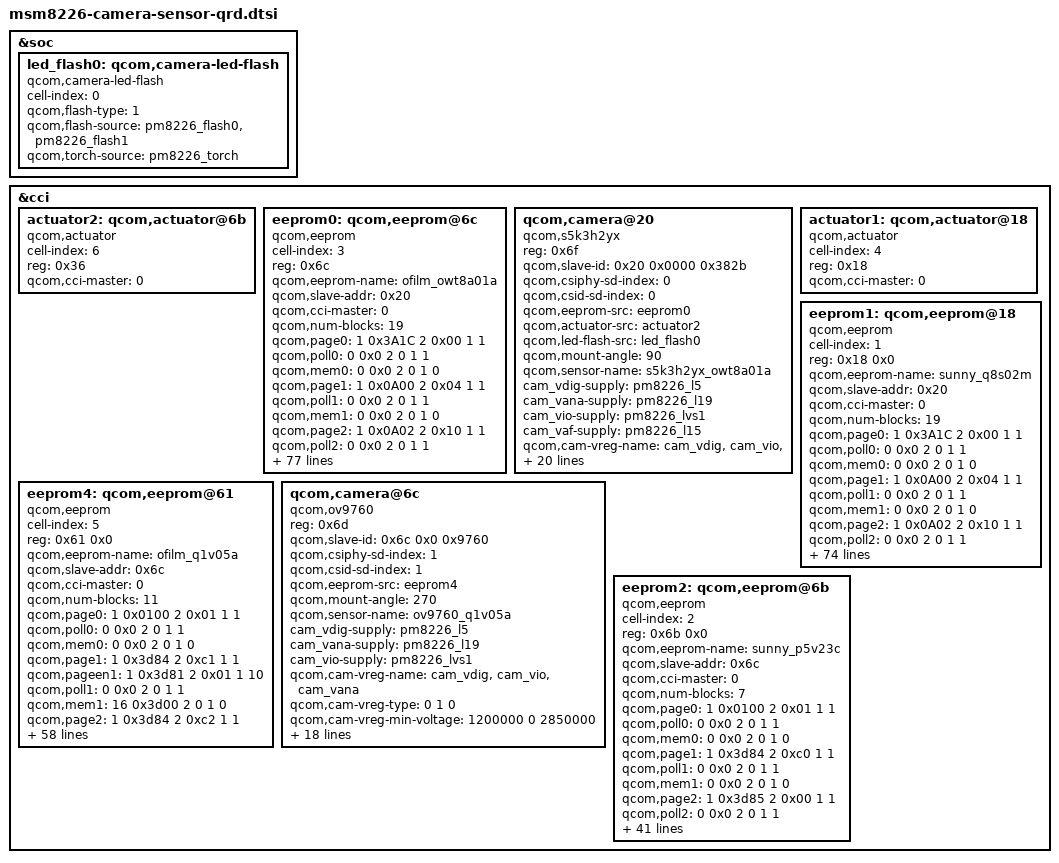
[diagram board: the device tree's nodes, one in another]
/*
 * Copyright (c) 2013, The Linux Foundation. All rights reserved.
 * Copyright (C) 2015 XiaoMi, Inc.
 *
 * This program is free software; you can redistribute it and/or modify
 * it under the terms of the GNU General Public License version 2 and
 * only version 2 as published by the Free Software Foundation.
 *
 * This program is distributed in the hope that it will be useful,
 * but WITHOUT ANY WARRANTY; without even the implied warranty of
 * MERCHANTABILITY or FITNESS FOR A PARTICULAR PURPOSE.  See the
 * GNU General Public License for more details.
 */

&soc {

	led_flash0: qcom,camera-led-flash {
		cell-index = <0>;
		compatible = "qcom,camera-led-flash";
		qcom,flash-type = <1>;
		qcom,flash-source = <&pm8226_flash0 &pm8226_flash1>;
		qcom,torch-source = <&pm8226_torch>;
	};
};

&cci {

	actuator2: qcom,actuator@6b {
		cell-index = <6>;
		reg = <0x36>;
		compatible = "qcom,actuator";
		qcom,cci-master = <0>;
	};

	eeprom0: qcom,eeprom@6c {
		cell-index = <3>;
		reg = <0x6c>;
		qcom,eeprom-name = "ofilm_owt8a01a";
		compatible = "qcom,eeprom";
		qcom,slave-addr = <0x20>;
		qcom,cci-master = <0>;

		qcom,num-blocks = <19>;

		qcom,page0 = <1 0x3A1C 2 0x00 1 1>;
		qcom,poll0 = <0 0x0 2 0 1 1>;
		qcom,mem0 = <0 0x0 2 0 1 0>;

		qcom,page1 = <1 0x0A00 2 0x04 1 1>;
		qcom,poll1 = <0 0x0 2 0 1 1>;
		qcom,mem1 = <0 0x0 2 0 1 0>;
		qcom,page2 = <1 0x0A02 2 0x10 1 1>;
		qcom,poll2 = <0 0x0 2 0 1 1>;
		qcom,mem2 = <0 0x0 2 0 1 0>;
		qcom,page3 = <1 0x0A00 2 0x01 1 20>;
		qcom,poll3 = <0 0x0 2 0 1 1>;
		qcom,mem3 = <8 0x0A04 2 0 1 1>;

		qcom,page4 = <1 0x0A00 2 0x04 1 1>;
		qcom,poll4 = <0 0x0 2 0 1 1>;
		qcom,mem4 = <0 0x0 2 0 1 0>;
		qcom,page5 = <1 0x0A02 2 0x11 1 1>;
		qcom,poll5 = <0 0x0 2 0 1 1>;
		qcom,mem5 = <0 0x00 2 0 1 0>;
		qcom,page6 = <1 0x0A00 2 0x01 1 20>;
		qcom,poll6 = <0 0x0 2 0 1 1>;
		qcom,mem6 = <8 0x0A04 2 0 1 1>;

		qcom,page7 = <1 0x0A00 2 0x04 1 1>;
		qcom,poll7 = <0 0x0 2 0 1 1>;
		qcom,mem7 = <0 0x0 2 0 1 0>;
		qcom,page8 = <1 0x0A02 2 0x12 1 10>;
		qcom,poll8 = <0 0x0 2 0 1 1>;
		qcom,mem8 = <0 0x0 2 0 1 0>;
		qcom,page9 = <1 0x0A00 2 0x01 1 20>;
		qcom,poll9 = <0 0x0 2 0 1 1>;
		qcom,mem9 = <8 0x0A04 2 0 1 1>;

		qcom,page10 = <1 0x0A00 2 0x04 1 1>;
		qcom,poll10 = <0 0x0 2 0 1 1>;
		qcom,mem10 = <0 0x0 2 0 1 0>;
		qcom,page11 = <1 0x0A02 2 0x09 1 10>;
		qcom,poll11 = <0 0x0 2 0 1 1>;
		qcom,mem11 = <0 0x0 2 0 1 0>;
		qcom,page12 = <1 0x0A00 2 0x01 1 20>;
		qcom,poll12 = <0 0x0 2 0 1 1>;
		qcom,mem12 = <3 0x0A04 2 0 1 1>;

		qcom,page13 = <1 0x0A00 2 0x04 1 1>;
		qcom,poll13 = <0 0x0 2 0 1 1>;
		qcom,mem13 = <0 0x0 2 0 1 0>;
		qcom,page14 = <1 0x0A00 2 0x00 1 1>;
		qcom,poll14 = <0 0x0 2 0 1 1>;
		qcom,mem14 = <0 0x0 2 0 1 0>;
		qcom,page15 = <1 0x0A04 2 0x08 1 1>;
		qcom,poll15 = <0 0x0 2 0 1 1>;
		qcom,mem15 = <0 0x0A04 2 0 1 0>;

		qcom,page16 = <1 0x0A04 2 0x03 1 1>;
		qcom,poll16 = <0 0x0 2 0 1 1>;
		qcom,mem16 = <9 0x0A04 2 0 1 1>;
		qcom,page17 = <1 0x0A04 2 0x03 1 1>;
		qcom,poll17 = <0 0x0 2 0 1 1>;
		qcom,mem17 = <9 0x0A04 2 0 1 1>;
		qcom,page18 = <1 0x0A04 2 0x03 1 1>;
		qcom,poll18 = <0 0x0 2 0 1 1>;
		qcom,mem18 = <0 0x0A04 2 0 1 1>;

		cam_vdig-supply = <&pm8226_l5>;
		cam_vana-supply = <&pm8226_l19>;
		cam_vio-supply = <&pm8226_lvs1>;
		qcom,cam-vreg-name = "cam_vdig","cam_vana", "cam_vio";
		qcom,cam-vreg-type = <0 1 2>;
		qcom,cam-vreg-min-voltage = <1200000 2850000 0>;
		qcom,cam-vreg-max-voltage = <1200000 2850000 0>;
		qcom,cam-vreg-op-mode = <200000 80000 0>;

		qcom,gpio-no-mux = <0>;
		gpios = <&msmgpio 26 0>,
				<&msmgpio 37 0>,
				<&msmgpio 36 0>;
		qcom,gpio-reset = <1>;
		qcom,gpio-standby = <2>;
		qcom,gpio-req-tbl-num = <0 1 2>;
		qcom,gpio-req-tbl-flags = <1 0 0>;
		qcom,gpio-req-tbl-label = "CAMIF_MCLK",
				"CAM_RESET1",
				"CAM_STANDBY";
		qcom,cam-power-seq-type = "sensor_vreg","sensor_vreg",
				"sensor_vreg", "sensor_clk",
				"sensor_gpio", "sensor_gpio",
				"sensor_gpio", "sensor_gpio";
		qcom,cam-power-seq-val = "cam_vdig","cam_vana",
				"cam_vio", "sensor_cam_mclk",
				"sensor_gpio_reset",
				"sensor_gpio_standby",
				"sensor_gpio_reset",
				"sensor_gpio_standby";
		qcom,cam-power-seq-cfg-val = <1 1 1 24000000 0 0 1 1>;
		qcom,cam-power-seq-delay = <1 1 1 20 10 10 10 10>;
	};

    qcom,camera@20 {
		compatible = "qcom,s5k3h2yx";
		reg = <0x6f>;
		qcom,slave-id = <0x20 0x0000 0x382b>;
		qcom,csiphy-sd-index = <0>;
		qcom,csid-sd-index = <0>;
		qcom,eeprom-src = <&eeprom0>;
		qcom,actuator-src = <&actuator2>;
		qcom,led-flash-src = <&led_flash0>;
		qcom,mount-angle = <90>;
		qcom,sensor-name = "s5k3h2yx_owt8a01a";
			cam_vdig-supply = <&pm8226_l5>;
			cam_vana-supply = <&pm8226_l19>;
			cam_vio-supply = <&pm8226_lvs1>;
			cam_vaf-supply = <&pm8226_l15>;
		qcom,cam-vreg-name = "cam_vdig", "cam_vio", "cam_vana",
			"cam_vaf";
		qcom,cam-vreg-type = <0 1 0 0>;
		qcom,cam-vreg-min-voltage = <1200000 0 2850000 2800000>;
		qcom,cam-vreg-max-voltage = <1200000 0 2850000 2800000>;
		qcom,cam-vreg-op-mode = <200000 0 80000 100000>;
		qcom,gpio-no-mux = <0>;
		gpios = <&msmgpio 26 0>,
				<&msmgpio 37 0>,
				<&msmgpio 36 0>;
		qcom,gpio-reset = <1>;
		qcom,gpio-standby = <2>;
		qcom,gpio-req-tbl-num = <0 1 2>;
		qcom,gpio-req-tbl-flags = <1 0 0>;
		qcom,gpio-req-tbl-label = "CAMIF_MCLK",
			"CAM_RESET1",
			"CAM_STANDBY";
		qcom,csi-lane-assign = <0x4320>;
		qcom,csi-lane-mask = <0x07>;
		qcom,sensor-position = <0>;
		qcom,sensor-mode = <1>;
		qcom,cci-master = <0>;
	};

	actuator1: qcom,actuator@18 {
		cell-index = <4>;
		reg = <0x18>;
		compatible = "qcom,actuator";
		qcom,cci-master = <0>;
	};

	eeprom1: qcom,eeprom@18 {
		cell-index = <1>;
		reg = <0x18 0x0>;
		qcom,eeprom-name = "sunny_q8s02m";
		compatible = "qcom,eeprom";
		qcom,slave-addr = <0x20>;
		qcom,cci-master = <0>;
		qcom,num-blocks = <19>;

		qcom,page0 = <1 0x3A1C 2 0x00 1 1>;
		qcom,poll0 = <0 0x0 2 0 1 1>;
		qcom,mem0 = <0 0x0 2 0 1 0>;

		qcom,page1 = <1 0x0A00 2 0x04 1 1>;
		qcom,poll1 = <0 0x0 2 0 1 1>;
		qcom,mem1 = <0 0x0 2 0 1 0>;
		qcom,page2 = <1 0x0A02 2 0x10 1 1>;
		qcom,poll2 = <0 0x0 2 0 1 1>;
		qcom,mem2 = <0 0x0 2 0 1 0>;
		qcom,page3 = <1 0x0A00 2 0x01 1 20>;
		qcom,poll3 = <0 0x0 2 0 1 1>;
		qcom,mem3 = <8 0x0A04 2 0 1 1>;

		qcom,page4 = <1 0x0A00 2 0x04 1 1>;
		qcom,poll4 = <0 0x0 2 0 1 1>;
		qcom,mem4 = <0 0x0 2 0 1 0>;
		qcom,page5 = <1 0x0A02 2 0x11 1 1>;
		qcom,poll5 = <0 0x0 2 0 1 1>;
		qcom,mem5 = <0 0x00 2 0 1 0>;
		qcom,page6 = <1 0x0A00 2 0x01 1 20>;
		qcom,poll6 = <0 0x0 2 0 1 1>;
		qcom,mem6 = <8 0x0A04 2 0 1 1>;

		qcom,page7 = <1 0x0A00 2 0x04 1 1>;
		qcom,poll7 = <0 0x0 2 0 1 1>;
		qcom,mem7 = <0 0x0 2 0 1 0>;
		qcom,page8 = <1 0x0A02 2 0x12 1 10>;
		qcom,poll8 = <0 0x0 2 0 1 1>;
		qcom,mem8 = <0 0x0 2 0 1 0>;
		qcom,page9 = <1 0x0A00 2 0x01 1 20>;
		qcom,poll9 = <0 0x0 2 0 1 1>;
		qcom,mem9 = <8 0x0A04 2 0 1 1>;

		qcom,page10 = <1 0x0A00 2 0x04 1 1>;
		qcom,poll10 = <0 0x0 2 0 1 1>;
		qcom,mem10 = <0 0x0 2 0 1 0>;
		qcom,page11 = <1 0x0A02 2 0x09 1 10>;
		qcom,poll11 = <0 0x0 2 0 1 1>;
		qcom,mem11 = <0 0x0 2 0 1 0>;
		qcom,page12 = <1 0x0A00 2 0x01 1 20>;
		qcom,poll12 = <0 0x0 2 0 1 1>;
		qcom,mem12 = <3 0x0A04 2 0 1 1>;

		qcom,page13 = <1 0x0A00 2 0x04 1 1>;
		qcom,poll13 = <0 0x0 2 0 1 1>;
		qcom,mem13 = <0 0x0 2 0 1 0>;
		qcom,page14 = <1 0x0A00 2 0x00 1 1>;
		qcom,poll14 = <0 0x0 2 0 1 1>;
		qcom,mem14 = <0 0x0 2 0 1 0>;
		qcom,page15 = <1 0x0A04 2 0x08 1 1>;
		qcom,poll15 = <0 0x0 2 0 1 1>;
		qcom,mem15 = <0 0x0A04 2 0 1 0>;

		qcom,page16 = <1 0x0A04 2 0x03 1 1>;
		qcom,poll16 = <0 0x0 2 0 1 1>;
		qcom,mem16 = <9 0x0A04 2 0 1 1>;
		qcom,page17 = <1 0x0A04 2 0x03 1 1>;
		qcom,poll17 = <0 0x0 2 0 1 1>;
		qcom,mem17 = <9 0x0A04 2 0 1 1>;
		qcom,page18 = <1 0x0A04 2 0x03 1 1>;
		qcom,poll18 = <0 0x0 2 0 1 1>;
		qcom,mem18 = <0 0x0A04 2 0 1 1>;

		cam_vdig-supply = <&pm8226_l5>;
		cam_vana-supply = <&pm8226_l19>;
		cam_vio-supply = <&pm8226_lvs1>;
		qcom,cam-vreg-name = "cam_vdig","cam_vana", "cam_vio";
		qcom,cam-vreg-type = <0 1 2>;
		qcom,cam-vreg-min-voltage = <1200000 2850000 0>;
		qcom,cam-vreg-max-voltage = <1200000 2850000 0>;
		qcom,cam-vreg-op-mode = <200000 80000 0>;
		qcom,gpio-no-mux = <0>;
		gpios = <&msmgpio 26 0>,
		        <&msmgpio 37 0>,
		        <&msmgpio 36 0>;
		qcom,gpio-reset = <1>;
		qcom,gpio-standby = <2>;
		qcom,gpio-req-tbl-num = <0 1 2>;
		qcom,gpio-req-tbl-flags = <1 0 0>;
		qcom,gpio-req-tbl-label = "CAMIF_MCLK",
		        "CAM_RESET1",
		        "CAM_STANDBY";
		qcom,cam-power-seq-type = "sensor_vreg","sensor_vreg",
		        "sensor_vreg", "sensor_clk",
		        "sensor_gpio", "sensor_gpio";
		qcom,cam-power-seq-val = "cam_vdig","cam_vana",
		        "cam_vio", "sensor_cam_mclk",
		        "sensor_gpio_reset",
		        "sensor_gpio_standby";
		qcom,cam-power-seq-cfg-val = <1 1 1 24000000 1 1>;
		qcom,cam-power-seq-delay = <1 1 1 5 5 10>;
	};

    eeprom4: qcom,eeprom@61{
		cell-index = <5>;
		reg = <0x61 0x0>;
		qcom,eeprom-name = "ofilm_q1v05a";
		compatible = "qcom,eeprom";
		qcom,slave-addr = <0x6c>;
		qcom,cci-master = <0>;
		qcom,num-blocks = <11>;

		qcom,page0 = <1 0x0100 2 0x01 1 1>;
		qcom,poll0 = <0 0x0 2 0 1 1>;
		qcom,mem0 = <0 0x0 2 0 1 0>;
		qcom,page1 = <1 0x3d84 2 0xc1 1 1>;
		qcom,pageen1 = <1 0x3d81 2 0x01 1 10>;
		qcom,poll1 = <0 0x0 2 0 1 1>;
		qcom,mem1 = <16 0x3d00 2 0 1 0>;
		qcom,page2 = <1 0x3d84 2 0xc2 1 1>;
		qcom,pageen2 = <1 0x3d81 2 0x01 1 10>;
		qcom,poll2 = <0 0x0 2 0 1 1>;
		qcom,mem2 = <16 0x3d00 2 0 1 0>;
		qcom,page3 = <1 0x3d84 2 0xc3 1 1>;
		qcom,pageen3 = <1 0x3d81 2 0x01 1 10>;
		qcom,poll3 = <0 0x0 2 0 1 1>;
		qcom,mem3 = <16 0x3d00 2 0 1 0>;
		qcom,page4 = <1 0x3d84 2 0xc4 1 1>;
		qcom,pageen4 = <1 0x3d81 2 0x01 1 10>;
		qcom,poll4 = <0 0x0 2 0 1 1>;
		qcom,mem4 = <16 0x3d00 2 0 1 0>;
		qcom,page5 = <1 0x3d84 2 0xc5 1 1>;
		qcom,pageen5 = <1 0x3d81 2 0x01 1 10>;
		qcom,poll5 = <0 0x0 2 0 1 1>;
		qcom,mem5 = <16 0x3d00 2 0 1 0>;
		qcom,page6 = <1 0x3d84 2 0xc6 1 1>;
		qcom,pageen6 = <1 0x3d81 2 0x01 1 10>;
		qcom,poll6 = <0 0x0 2 0 1 1>;
		qcom,mem6 = <16 0x3d00 2 0 1 0>;
		qcom,page7 = <1 0x3d84 2 0xc7 1 1>;
		qcom,pageen7 = <1 0x3d81 2 0x01 1 10>;
		qcom,poll7 = <0 0x0 2 0 1 1>;
		qcom,mem7 = <16 0x3d00 2 0 1 0>;
		qcom,page8 = <1 0x3d84 2 0xc8 1 1>;
		qcom,pageen8 = <1 0x3d81 2 0x01 1 10>;
		qcom,poll8 = <0 0x0 2 0 1 1>;
		qcom,mem8 = <16 0x3d00 2 0 1 0>;
		qcom,page9 = <1 0x3d84 2 0xc9 1 1>;
		qcom,pageen9 = <1 0x3d81 2 0x01 1 10>;
		qcom,poll9 = <0 0x0 2 0 1 1>;
		qcom,mem9 = <16 0x3d00 2 0 1 0>;
		qcom,page10 = <1 0x3d84 2 0xdf 1 1>;
		qcom,pageen10 = <1 0x3d81 2 0x01 1 10>;
		qcom,poll10 = <0 0x0 2 0 1 1>;
		qcom,mem10 = <16 0x3d00 2 0 1 0>;

		cam_vio-supply = <&pm8226_lvs1>;
		cam_vdig-supply = <&pm8226_l5>;
		qcom,cam-vreg-name = "cam_vdig", "cam_vio";
		qcom,cam-vreg-type = <0 1>;
		qcom,cam-vreg-min-voltage = <1200000 0>;
		qcom,cam-vreg-max-voltage = <1200000 0>;
		qcom,cam-vreg-op-mode = <200000 0>;
		qcom,gpio-no-mux = <0>;
		gpios = <&msmgpio 26 0>,
				<&msmgpio 28 0>,
				<&msmgpio 35 0>;
		qcom,gpio-reset = <1>;
		qcom,gpio-standby = <2>;
		qcom,gpio-req-tbl-num = <0 1 2>;
		qcom,gpio-req-tbl-flags = <1 0 0>;
		qcom,gpio-req-tbl-label = "CAMIF_MCLK",
			"CAM_RESET",
			"CAM_STANDBY";
		qcom,cam-power-seq-type = "sensor_vreg",
			"sensor_vreg","sensor_clk","sensor_gpio",
			"sensor_gpio";
		qcom,cam-power-seq-val = "cam_vdig","cam_vio",
			"sensor_cam_mclk","sensor_gpio_reset",
			"sensor_gpio_standby";
		qcom,cam-power-seq-cfg-val = <1 1 24000000 1 1>;
		qcom,cam-power-seq-delay = <1 1 10 10 10>;
	};

	qcom,camera@6c {
		compatible = "qcom,ov9760";
		reg = <0x6d>;
		qcom,slave-id = <0x6c 0x0 0x9760>;
		qcom,csiphy-sd-index = <1>;
		qcom,csid-sd-index = <1>;
		qcom,eeprom-src = <&eeprom4>;
		qcom,mount-angle = <270>;
		qcom,sensor-name = "ov9760_q1v05a";
		cam_vdig-supply = <&pm8226_l5>;
		cam_vana-supply = <&pm8226_l19>;
		cam_vio-supply = <&pm8226_lvs1>;
		qcom,cam-vreg-name = "cam_vdig", "cam_vio", "cam_vana";
		qcom,cam-vreg-type = <0 1 0>;
		qcom,cam-vreg-min-voltage = <1200000 0 2850000>;
		qcom,cam-vreg-max-voltage = <1200000 0 2850000>;
		qcom,cam-vreg-op-mode = <200000 0 80000>;
		qcom,gpio-no-mux = <0>;
		gpios = <&msmgpio 26 0>,
				<&msmgpio 28 0>,
				<&msmgpio 35 0>;
		qcom,gpio-reset = <1>;
		qcom,gpio-standby = <2>;
		qcom,gpio-req-tbl-num = <0 1 2>;
		qcom,gpio-req-tbl-flags = <1 0 0>;
		qcom,gpio-req-tbl-label = "CAMIF_MCLK",
				"CAM_RESET",
				"CAM_STANDBY";
		qcom,gpio-set-tbl-num = <1 1>;
		qcom,gpio-set-tbl-flags = <0 2>;
		qcom,gpio-set-tbl-delay = <1000 4000>;
		qcom,csi-lane-assign = <0x4320>;
		qcom,csi-lane-mask = <0x3>;
		qcom,sensor-position = <1>;
		qcom,sensor-mode = <1>;
		qcom,cci-master = <0>;
		status = "ok";
	};

	eeprom2: qcom,eeprom@6b{
		cell-index = <2>;
		reg = <0x6b 0x0>;
		qcom,eeprom-name = "sunny_p5v23c";
		compatible = "qcom,eeprom";
		qcom,slave-addr = <0x6c>;
		qcom,cci-master = <0>;
		qcom,num-blocks = <7>;

		qcom,page0 = <1 0x0100 2 0x01 1 1>;
		qcom,poll0 = <0 0x0 2 0 1 1>;
		qcom,mem0 = <0 0x0 2 0 1 0>;

		qcom,page1 = <1 0x3d84 2 0xc0 1 1>;
		qcom,poll1 = <0 0x0 2 0 1 1>;
		qcom,mem1 = <0 0x0 2 0 1 0>;
		qcom,page2 = <1 0x3d85 2 0x00 1 1>;
		qcom,poll2 = <0 0x0 2 0 1 1>;
		qcom,mem2 = <0 0x0 2 0 1 0>;
		qcom,page3 = <1 0x3d86 2 0x0f 1 1>;
		qcom,pageen3 = <1 0x3d81 2 0x01 1 10>;
		qcom,poll3 = <0 0x0 2 0 1 1>;
		qcom,mem3 = <16 0x3d00 2 0 1 0>;

		qcom,page4 = <1 0x3d84 2 0xc0 1 1>;
		qcom,poll4 = <0 0x0 2 0 1 1>;
		qcom,mem4 = <0 0x0 2 0 1 0>;
		qcom,page5 = <1 0x3d85 2 0x10 1 1>;
		qcom,poll5 = <0 0x0 2 0 1 1>;
		qcom,mem5 = <0 0x0 2 0 1 0>;
		qcom,page6 = <1 0x3d86 2 0x1f 1 1>;
		qcom,pageen6 = <1 0x3d81 2 0x01 1 10>;
		qcom,poll6 = <0 0x0 2 0 1 1>;
		qcom,mem6 = <16 0x3d00 2 0 1 0>;

		cam_vio-supply = <&pm8226_lvs1>;
		cam_vana-supply = <&pm8226_l19>;
		qcom,cam-vreg-name = "cam_vdig", "cam_vio", "cam_vana";
		qcom,cam-vreg-type = <0 1 0>;
		qcom,cam-vreg-min-voltage = <1200000 0 2850000>;
		qcom,cam-vreg-max-voltage = <1200000 0 2850000>;
		qcom,cam-vreg-op-mode = <200000 0 80000>;
		qcom,gpio-no-mux = <0>;
		gpios = <&msmgpio 26 0>,
			<&msmgpio 28 0>,
			<&msmgpio 35 0>,
			<&msmgpio 21 0>;
		qcom,gpio-reset = <1>;
		qcom,gpio-standby = <2>;
		qcom,gpio-vdig = <3>;
		qcom,gpio-req-tbl-num = <0 1 2 3>;
		qcom,gpio-req-tbl-flags = <1 0 0 0>;
		qcom,gpio-req-tbl-label = "CAMIF_MCLK",
			"CAM_RESET",
			"CAM_STANDBY",
			"CAM_VDIG";
		qcom,cam-power-seq-type = "sensor_vreg",
			"sensor_vreg", "sensor_gpio",
			"sensor_gpio", "sensor_gpio" , "sensor_clk";
		qcom,cam-power-seq-val = "cam_vio", "cam_vana","sensor_gpio_vdig",
			 "sensor_gpio_reset",
			"sensor_gpio_standby","sensor_cam_mclk" ;
		qcom,cam-power-seq-cfg-val = <1 1 1 1 1 24000000>;
		qcom,cam-power-seq-delay = <1 1 10 10 10 5>;
	};
};
